# T113-S3 register map
Vendor: Allwinner; Series: T113-S3; File version: 0.1
CPU: other 0, little endian, MPU, no FPU, 0 interrupt priority bits
Registers are 32-bit, read-write, reset 0x0 unless marked. A register's access mark holds for its fields unless they carry their own. Offsets are from the block's base; [hi:lo] are bit positions; 'fields as' and 'values as' point back to an identical list.

## CSIC_TOP
Base 0x05800800
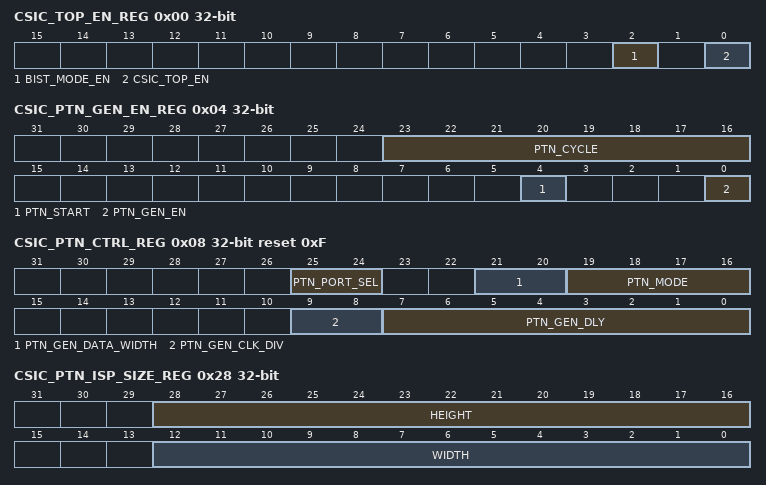
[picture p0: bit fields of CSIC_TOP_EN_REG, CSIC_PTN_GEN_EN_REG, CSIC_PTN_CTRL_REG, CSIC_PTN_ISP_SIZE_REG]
0x00 CSIC_TOP_EN_REG — CSIC TOP Enable Register
  [2] BIST_MODE_EN — 0: Closed 1: EN BIST TEST
    0=Closed; 1=EN (EN BIST TEST)
  [0] CSIC_TOP_EN — 0: Reset and disable the CSIC module 1: Enable the CSIC module
    0=Reset and disable the CSIC module; 1=Enable the CSIC module
0x04 CSIC_PTN_GEN_EN_REG — CSIC Pattern Generation Enable Register
  [23:16] PTN_CYCLE — Pattern generating cycle counter. The pattern in dram will be generated in cycles of PTN_CYCLE+1.
  [4] PTN_START — CSIC Pattern Generating Start 0: Finish 1: Start Software writes this bit to `1` to start pattern generating from DRAM. When finished, the hardware will clear this bit to `0` automatically. Generating cycles depends on PTN_CYCLE.
    0=Finish; 1=Start Software writes this bit to `1` to start pattern generating from DRAM. When finished, the hardware will clear this bit to `0` automatically. Generating cycles depends on PTN_CYCLE.
  [0] PTN_GEN_EN — Pattern Generation Enable
0x08 CSIC_PTN_CTRL_REG reset 0xF — CSIC Pattern Control Register
  [25:24] PTN_PORT_SEL — Pattern Generator output port selection 10:NCSIC0 others:reserved
  [21:20] PTN_GEN_DATA_WIDTH — 00:8-bit 01:10-bit 10:12-bit 11:reserved
  [19:16] PTN_MODE — Pattern mode selection 0000-0011:reserved 0100:NCSIC YUV 8 bits width 0101:NCSIC YUV 16 bits width 0110:reserved 0111:reserved 1000:BT656 8 bits width 1001:BT656 16 bits width 1010:reserved 1011:reserved 1100:BAYER 12 bits for ISPFE 1101:UYVY422 12 bits for ISPFE 1110:UYVY420 12 bits for ISPFE 1111:reserved
  [9:8] PTN_GEN_CLK_DIV — Packet generator clock divider
  [7:0] PTN_GEN_DLY — Clocks delayed before pattern generating start.
0x20 CSIC_PTN_LEN_REG — CSIC Pattern Generation Length Register
  [31:0] PTN_LEN — The pattern length in byte when generating pattern.
0x24 CSIC_PTN_ADDR_REG — CSIC Pattern Generation Address Register
  [31:0] PTN_ADDR — The pattern DRAM address when generating pattern.
0x28 CSIC_PTN_ISP_SIZE_REG — CSIC Pattern ISP Size Register
  [28:16] HEIGHT — Height Vertical size, only valid for ISP mode pattern generation.
  [12:0] WIDTH — Width Horizontal size, only valid for ISP mode pattern generation.
0xA0 CSIC_DMA0_INPUT_SEL_REG — CSIC DMA0 Input Select Register
  [3:0] DMA0 — Input Select 0000: input from ISP0 CH0 0001: input from ISP0 CH1 0010: input from ISP0 CH2 0011: input from ISP0 CH3 Others: Reserved
    0=input_from_ISP0_CH0; 1=input_from_ISP0_CH1; 2=input_from_ISP0_CH2; 3=input from ISP0 CH3 Others: Reserved
0xA4 CSIC_DMA1_INPUT_SEL_REG — CSIC DMA1 Input Select Register
  [3:0] DMA1 — Input Select 0000: input from ISP0 CH0 0001: input from ISP0 CH1 0010: input from ISP0 CH2 0011: input from ISP0 CH3 Others: Reserved
    values as CSIC_DMA0_INPUT_SEL_REG.DMA0
0xDC CSIC_BIST_CS_REG — CSIC BIST CS Register
  [2:0] BIST_CS — 000: Set when BK0 memory bist 001: Set when BK1 memory bist Others: Reserved
    0=Set when BK0 memory bist; 1=Set when BK1 memory bist Others: Reserved
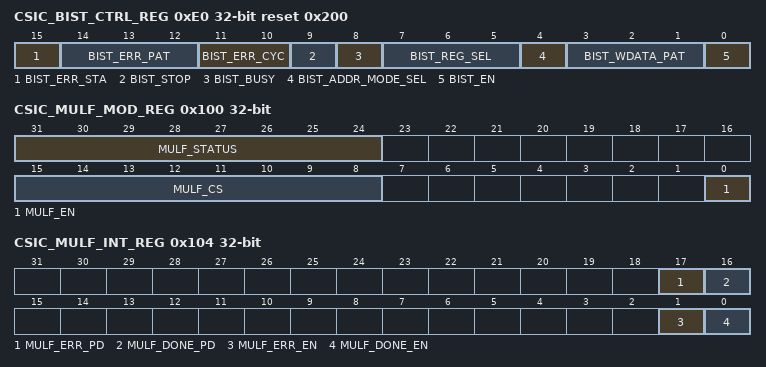
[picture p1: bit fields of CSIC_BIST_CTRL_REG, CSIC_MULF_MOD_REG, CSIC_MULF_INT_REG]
0xE0 CSIC_BIST_CTRL_REG reset 0x200 — CSIC BIST Control Register
  [15] BIST_ERR_STA ro — BIST Error Status 0: No effect 1: Error
    0=No_effect; 1=Error
  [14:12] BIST_ERR_PAT ro — BIST Error Pattern
  [11:10] BIST_ERR_CYC ro — BIST Error Cycle
  [9] BIST_STOP ro — BIST STOP 0: Running 1: Stop
    0=Running; 1=Stop
  [8] BIST_BUSY ro — BIST Busy 0: Idle 1: Busy
    0=Idle; 1=Busy
  [7:5] BIST_REG_SEL — BIST REG select
  [4] BIST_ADDR_MODE_SEL — BIST Address Mode Select
  [3:1] BIST_WDATA_PAT — BIST Write Data Pattern 000: 0x00000000 001: 0x55555555 010: 0x33333333 011: 0x0F0F0F0F 100: 0x00FF00FF 101: 0x0000FFFF others: Reserved
    0=_0x00000000; 1=_0x55555555; 2=_0x33333333; 3=_0x0F0F0F0F; 4=_0x00FF00FF; 5=0x0000FFFF others: Reserved
  [0] BIST_EN — BIST Enable A positive will trigger the BIST to start.
0xE4 CSIC_BIST_START_ADDR_REG — CSIC BIST Start Register
  [31:0] BIST — Start Address BIST Start Address. It is 32-bit aligned.
0xE8 CSIC_BIST_END_ADDR_REG — CSIC BIST End Register
  [31:0] BIST — END Address BIST END Address. It is 32-bit aligned.
0xEC CSIC_BIST_DATA_MASK_REG — CSIC BIST Data Mask Register
  [31:0] BIST_DATA_MASK — BIST Data Mask 0: Unmask 1: Mask
0xF0 CSIC_MBUS_REQ_MAX_REG reset 0xF — CSIC MBUS REQ MAX Register
  [4:0] MCSI_MEM_REQ_MAX — Maximum of request commands for the master granted in MCSI_MEM arbiter is N+1.
0x100 CSIC_MULF_MOD_REG — CSIC Multi-Frame Mode Register
  [31:24] MULF_STATUS ro, [15:8] MULF_CS, [0] MULF_EN
0x104 CSIC_MULF_INT_REG — CSIC Multi-Frame Interrupt Register
  [17] MULF_ERR_PD write-1-clears, [16] MULF_DONE_PD write-1-clears, [1] MULF_ERR_EN, [0] MULF_DONE_EN
